VERSION ""

NS_ :

BS_:

BU_: TTC_32 TTC_580

BO_ 769 SENSOR_INFO_1: 2 TTC_32
 SG_ QA_PROX_S2 : 8|1@1+ (1,0) [0|1] "mV"  TTC_580
 SG_ QA_PROX_S1 : 0|1@1+ (1,0) [0|1] "mV"  TTC_580

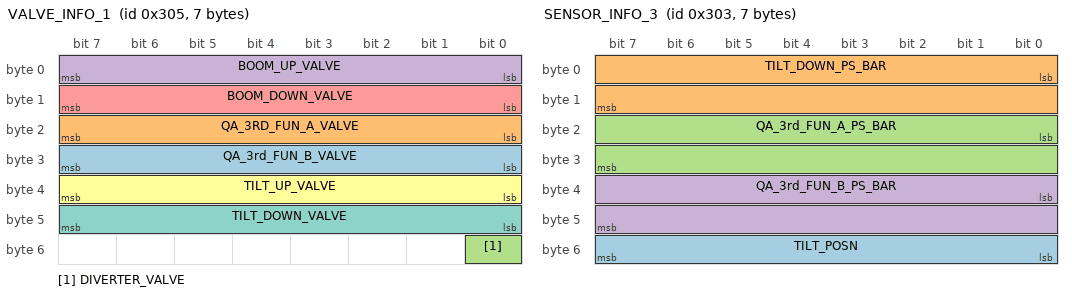
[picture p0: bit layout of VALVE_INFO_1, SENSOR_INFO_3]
BO_ 773 VALVE_INFO_1: 7 TTC_580
 SG_ QA_3rd_FUN_B_VALVE : 24|8@1+ (1,0) [0|100] "%"  TTC_32
 SG_ QA_3RD_FUN_A_VALVE : 16|8@1+ (1,0) [0|100] "%"  TTC_32
 SG_ DIVERTER_VALVE : 48|1@1+ (1,0) [0|1] "%"  TTC_32
 SG_ BOOM_UP_VALVE : 0|8@1+ (1,0) [0|100] "%"  TTC_32
 SG_ BOOM_DOWN_VALVE : 8|8@1+ (1,0) [0|100] "%"  TTC_32
 SG_ TILT_UP_VALVE : 32|8@1+ (1,0) [0|100] "%"  TTC_32
 SG_ TILT_DOWN_VALVE : 40|8@1+ (1,0) [0|100] "%"  TTC_32

BO_ 771 SENSOR_INFO_3: 7 TTC_32
 SG_ TILT_POSN : 48|8@1+ (1,0) [0|255] "mV"  TTC_580
 SG_ TILT_DOWN_PS_BAR : 0|16@1+ (1,0) [0|65535] "mV"  TTC_580
 SG_ QA_3rd_FUN_A_PS_BAR : 16|16@1+ (1,0) [0|65535] "mV"  TTC_580
 SG_ QA_3rd_FUN_B_PS_BAR : 32|16@1+ (1,0) [0|65535] "mV"  TTC_580

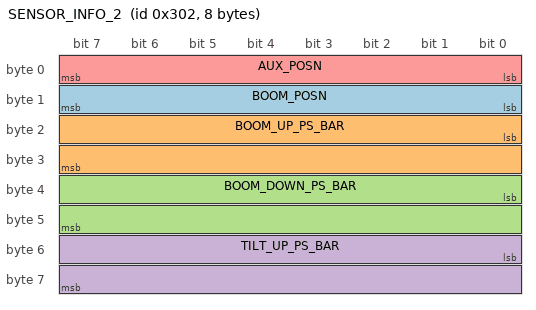
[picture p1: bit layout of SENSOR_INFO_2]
BO_ 770 SENSOR_INFO_2: 8 TTC_32
 SG_ BOOM_POSN : 8|8@1+ (1,0) [0|255] "mV"  TTC_580
 SG_ BOOM_UP_PS_BAR : 16|16@1+ (1,0) [0|65535] "mV"  TTC_580
 SG_ BOOM_DOWN_PS_BAR : 32|16@1+ (1,0) [0|65535] "mV"  TTC_580
 SG_ TILT_UP_PS_BAR : 48|16@1+ (1,0) [0|65535] "mV"  TTC_580
 SG_ AUX_POSN : 0|8@1+ (1,0) [0|255] "mV"  TTC_580

BA_DEF_  "BusType" STRING ;
BA_DEF_DEF_  "BusType" "CAN";
